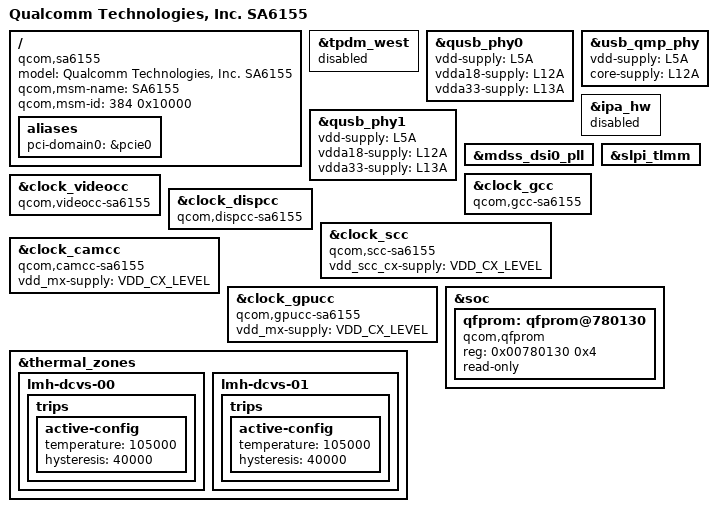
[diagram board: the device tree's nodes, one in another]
/* Copyright (c) 2018-2019, The Linux Foundation. All rights reserved.
 *
 * This program is free software; you can redistribute it and/or modify
 * it under the terms of the GNU General Public License version 2 and
 * only version 2 as published by the Free Software Foundation.
 *
 * This program is distributed in the hope that it will be useful,
 * but WITHOUT ANY WARRANTY; without even the implied warranty of
 * MERCHANTABILITY or FITNESS FOR A PARTICULAR PURPOSE.  See the
 * GNU General Public License for more details.
 */

#include "sm6150.dtsi"
#include "sa6155-pmic.dtsi"
#include "sa6155-display.dtsi"

/ {
	model = "Qualcomm Technologies, Inc. SA6155";
	compatible = "qcom,sa6155";
	qcom,msm-name = "SA6155";
	qcom,msm-id = <384 0x10000>;

	aliases {
		pci-domain0 = &pcie0; /* PCIe0 domain */
	};
};

&tpdm_west {
	status = "disabled";
};

&qusb_phy0 {
	vdd-supply = <&L5A>;
	vdda18-supply = <&L12A>;
	vdda33-supply = <&L13A>;
};

&usb_qmp_phy {
	vdd-supply = <&L5A>;
	core-supply = <&L12A>;
};

&qusb_phy1 {
	vdd-supply = <&L5A>;
	vdda18-supply = <&L12A>;
	vdda33-supply = <&L13A>;
};

&ipa_hw {
	status="disabled";
};

&mdss_dsi0_pll {
	/delete-property/ qcom,dsi-pll-ssc-en;
};

&slpi_tlmm {
	status = "ok";
};

&clock_gcc {
	compatible = "qcom,gcc-sa6155", "syscon";
	/delete-property/ protected-clocks;
};

&clock_videocc {
	compatible = "qcom,videocc-sa6155", "syscon";
};

&clock_dispcc {
	compatible = "qcom,dispcc-sa6155", "syscon";
};

&clock_scc {
	compatible = "qcom,scc-sa6155", "syscon";
	vdd_scc_cx-supply = <&VDD_CX_LEVEL>;
	status = "ok";
};

&clock_camcc {
	compatible = "qcom,camcc-sa6155", "syscon";
	vdd_mx-supply = <&VDD_CX_LEVEL>;
};

&clock_gpucc {
	compatible = "qcom,gpucc-sa6155", "syscon";
	vdd_mx-supply = <&VDD_CX_LEVEL>;
};

#include "sa6155-pcie.dtsi"

&soc {
	qfprom: qfprom@780130 {
		compatible = "qcom,qfprom";
		reg = <0x00780130 0x4>;
		#address-cells = <1>;
		#size-cells = <1>;
		read-only;
		ranges;
	};
};

&thermal_zones {
	lmh-dcvs-00 {
		trips {
			active-config {
				temperature = <105000>;
				hysteresis = <40000>;
			};
		};
	};

	lmh-dcvs-01 {
		trips {
			active-config {
				temperature = <105000>;
				hysteresis = <40000>;
			};
		};
	};
};
